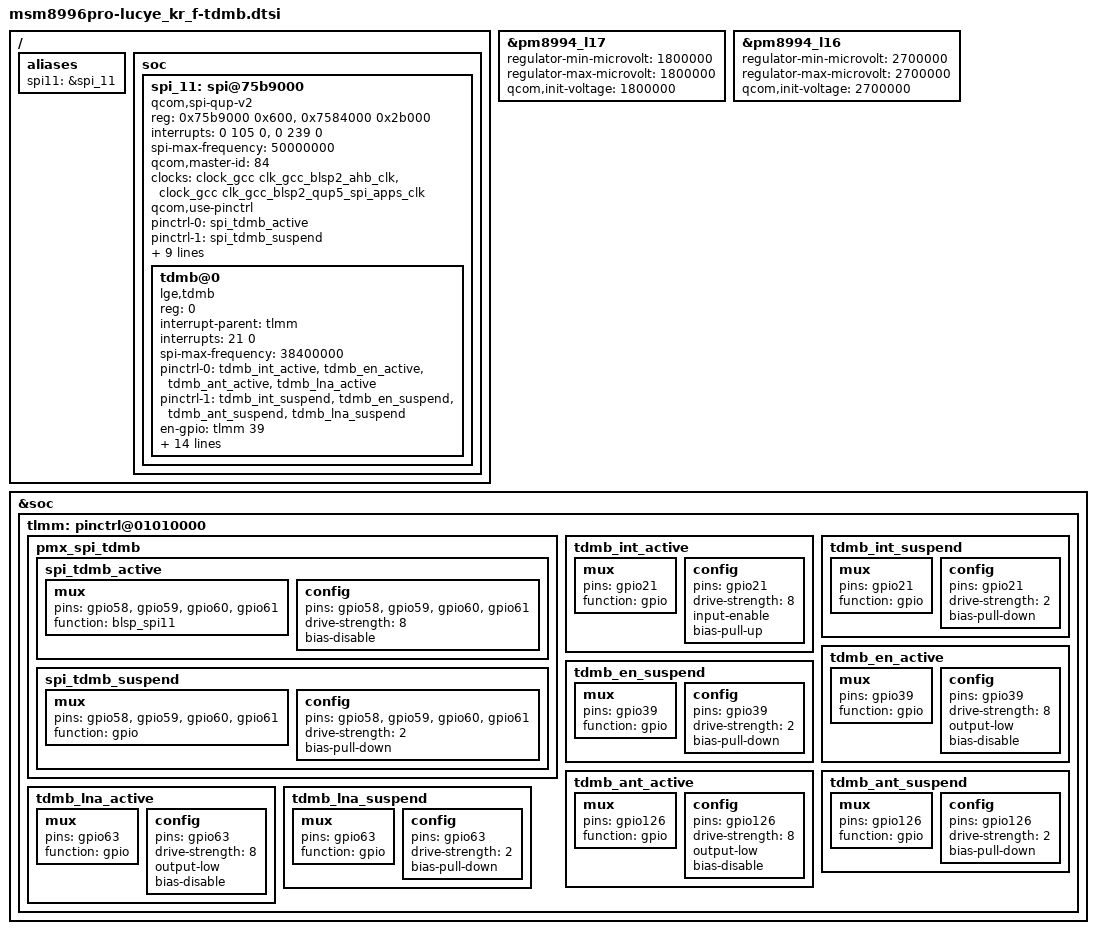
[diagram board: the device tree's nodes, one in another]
/* Copyright (c) 2014, The Linux Foundation. All rights reserved.
 *
 * This program is free software; you can redistribute it and/or modify
 * it under the terms of the GNU General Public License version 2 and
 * only version 2 as published by the Free Software Foundation.
 *
 * This program is distributed in the hope that it will be useful,
 * but WITHOUT ANY WARRANTY; without even the implied warranty of
 * MERCHANTABILITY or FITNESS FOR A PARTICULAR PURPOSE.  See the
 * GNU General Public License for more details.
 */

&pm8994_l17 {
	regulator-min-microvolt = <1800000>;
	regulator-max-microvolt = <1800000>;
	qcom,init-voltage = <1800000>;
	status = "ok";
};

&pm8994_l16 {
	regulator-min-microvolt = <2700000>;
	regulator-max-microvolt = <2700000>;
	qcom,init-voltage = <2700000>;
	status = "ok";
};

/ {
	aliases {
		spi11 = &spi_11;
	};

	soc {
		spi_11: spi@75b9000{	// [Modified] QUP_BASE address for BLSP# QUP# (ref. AP datasheet, This model use BLSP-2 QUP4)
			status = "ok";
			compatible = "qcom,spi-qup-v2"; // [Fixed] Should be "qcom,spi-qup-v2".

			// [Fixed] Address, size for slave chips.
			#address-cells = <1>;
			#size-cells = <0>;

			/* [Fixed] Resister region names referenced in reg.
				"spi_physical"     : Physical address of controller register blocks.
				when use BAM mode, add "spi_bam_physical"
				"spi_bam_physical" : Physical address of BAM controller.
				Keep the same names. */
			reg-names = "spi_physical", "spi_bam_physical";

			/* [Modified] Modify the reg field as below to add BLSP BAM base address (ref. AP datasheet)
				First Row is BLSP_QUP base address, size,
				Second Row is BAM address, size. */
			reg = <0x75b9000 0x600>, <0x7584000 0x2b000>;

			/* [Fixed] Interrupt resource names referenced in interrupts.
				"spi_irq"     : QUP-core interrupt
				when use BAM mode, add "spi_bam_irq"
				"spi_bam_irq" : BAM interrupt
				Keep the same names. */
			interrupt-names = "spi_irq", "spi_bam_irq";

			/* [Modified] Replace the interrupt filed. (ref. AP datasheet)
				First Field  : SPI interrupt, keep 0
				Second Field : Interrupt #
				Third Field  : Trigger type, keep 0
				First Row is BLSP_QUP base, Second Row is BAM. */
			interrupts = <0 105 0>, <0 239 0>;

			// [Fixed] Specifies maximum SPI clock frequency of AP(50 MHz). (ref. QCT SPI datasheet)
			spi-max-frequency = <50000000>;

			// [Modified] BLSP bus master ID. (ref. AP datasheet)
			qcom,master-id = <84>;

			// [Fixed] Set up the clocks, Keep the same names.
			clock-names = "iface_clk", "core_clk";
			/* [Modified]
				Add node to BLSP# AHB clock,
				Add node to QUP Core clock (BLSP# QUP#)
				Note : In clock QUP Core is label #1 to X. So QUP0 would be label as QUP1. */
			clocks = <&clock_gcc clk_gcc_blsp2_ahb_clk>, <&clock_gcc clk_gcc_blsp2_qup5_spi_apps_clk>;

			// [Fixed] When use pinctrl, enable.
			qcom,use-pinctrl;
			// [Fixed] Must contain "spi_default" and "spi_sleep" if pinctrl is to be used. Keep the same names.
			pinctrl-names = "spi_default","spi_sleep";
			/* [Fixed] List of phandles, each pointing at a pin configuration node within a pin controller.
				The list of names to assign states, List entry 0 defines the name for integer state ID 0... */
			pinctrl-0 = <&spi_tdmb_active>;
			pinctrl-1 = <&spi_tdmb_suspend>;

			/* [Modified] Set SPI GPIO (mosi, miso, cs, clk)
				tlmm is the parent, second # is gpio #, third flag keep it 0. */
			qcom,gpio-mosi = <&tlmm 58 0x00>;
			qcom,gpio-miso = <&tlmm 59 0x00>;
			qcom,gpio-cs0 = <&tlmm 60 0x00>;
			qcom,gpio-clk = <&tlmm 61 0x00>;

			// [Fixed] QUP uses infinite-mode. set zero
			qcom,infinite-mode = <0>;
			// [Fixed] When use BAM mode, enable.
			qcom,use-bam;
			// [Fixed] Version register exists.
			qcom,ver-reg-exists;
			// [Modified] Add consumer and producer pipes (ref. AP datasheet)
			qcom,bam-consumer-pipe-index = <20>; // Consumer pipe from AP BLSP SPI pipe assignment
			qcom,bam-producer-pipe-index = <21>; // Producer pipe from AP BLSP SPI pipe assignment
		};
	};
};

&spi_11 {
        tdmb@0 {
            compatible = "lge,tdmb"; // [Fixed] Should be "lge,tdmb".
	    reg = <0>;

            /* [Fixed] parents's node name ("tlmm" on sm8996) */
            interrupt-parent = <&tlmm>;

            /* [Modified] Set DMB_INT GPIO, first # is gpio #, second flag keep it 0. */
            interrupts = <21 0>;

            /* [Fixed] Specifies maximum SPI clock frequency of DMB chipset(38.4 MHz). (ref. FC8080 datasheet) */
            spi-max-frequency = <38400000>;

            /* [Fixed] The list of names to assign states, List entry 0,1,2... define the name for integer state ID 0,1,2...
                        - tdmb_pin_active : set to pinctrl-0 list (set to active)
                        - tdmb_pin_sleep : set to pinctrl-1 list (set to sleep) 	*/
            pinctrl-names = "tdmb_pin_active", "tdmb_pin_sleep";

            /* [Modified] The pin cofig lists can be for control pin.
                            - pinctrl-0 : active state
                            - pinctrl-1 : active sleep(suspend)
                          The pin config lists shall be defined in the "(model)-pinctrl.dtsi" file
                          The control pins lists are interrupt(tdmb_int), enable(tdmb_en),
                          FM/DMB antenna swtiching(tdmb_ant), LNA gain control & enable(tdmb_lna), LDO enable(tdmb_lna_en)
                          Additional items may vary depending on model schematic. */
            pinctrl-0 = <&tdmb_int_active>, <&tdmb_en_active>, <&tdmb_ant_active>, <&tdmb_lna_active>;
            pinctrl-1 = <&tdmb_int_suspend>, <&tdmb_en_suspend>, <&tdmb_ant_suspend>, <&tdmb_lna_suspend>;

            /* [Modified] first is parents's node, second # is gpio #, third flag keep it 0. */
            en-gpio = <&tlmm 39 0>;
            lna-gc-gpio = <&tlmm 63 0>;
            //lna-en-gpio = <&tlmm 164 0>;
            //ldo-en-gpio = <&tlmm 11 0>;

            /* [Modified] when use DMB_EN & LDO_EN same gpio, change below property to 1 */
            dmb-en-lna-en-same-gpio = <0>;


            /* [ANT Switch Information]
             *  1) FM/DMB Switch                               : Control
             *  2) TDMB ANT connected to port1 (High) and FM_ANT connected to port2 (Low), so active mode is high
             */

            /* [Modified] when use ant switching, change use-ant-sw to 1, and set ant active mode (high(1) or low(0)), ant-gpio.
               ant-sw-apio should be dmb_ant's Gpio number */
            use-ant-sw = <1>;
            ant-sw-gpio = <&tlmm 126 0>;
            ant-sw-active-value = <0>;

            /* [CLK Information] */
            /* [Modified] when use pmic clk buffer, change use-xtal to 0 and set xtal-freq(DMB Chipset Core clk), interface-freq(SPI interface clk) inter value in kHz. */
            use-xtal = <0>;
            xtal-freq = <19200>;
            interface-freq = <19200>;

            /* [Modified] when using clock buffer, you should check which clock buffer used for dmb device */
            clock-names = "tdmb_xo";
            clocks = <&clock_gcc clk_bb_clk2>;

            /* [Power Supply Description Information]
             *  1) ANT-SW LDO   (pm8150_l16)                 : V2.7, Not always power, power on/off control need
             *  2) DMB LDO      (pm8150_l12)                    : V1.8, always power, power on/off control not need
             *  3) LNA LDO      (pm8150_s4)                     : V1.8, always power, power on/off control not need
             */

            /* [Modified] When use ldo for RFSW, change ctrl-ant-sw-ldo to 1, and ant-sw-supply set the appropriate chipset & power function such as <&pm8953_l10>
               If no use case, change ctrl-ant-sw-ldo to 0, and ant-sw-supply set such as <&chipset#_l??>*/
            ctrl-ant-sw-ldo = <0>;
            //ant-sw-ldo-supply = <&chipset#_l??>;

            /* [Modified] when use ldo for LDO_IN, change ctrl-dmb-ldo to 1, and dmb-ldo-supply set the appropriate chipset & power function such as <&pm8953_l10>
              If no use case, change ctrl-dmb-ldo to 0, and dmb-ldo-supply set such as <&chipset#_l??>*/
            ctrl-dmb-ldo = <1>;
            dmb-ldo-supply = <&pm8994_l17>;

            /* [Modified] when use ldo for LNA(U1800), change ctrl-lna-ldo to 1, and lna-ldo-supply set the appropriate chipset & power function such as <&pm8953_l10>
               If no use case, change ctrl-lna-ldo to 0, and lna-ldo-supply set such as <&chipset#_l??>*/
            ctrl-lna-ldo = <1>;
            lna_ldo-supply = <&pm8994_l16>;
        };
};

&soc {
    tlmm: pinctrl@01010000 {
        pmx_spi_tdmb {
            spi_tdmb_active: spi_tdmb_active {
                mux {
                    pins =  "gpio58", "gpio59", "gpio60", "gpio61";
                    function = "blsp_spi11";
                };

                config {
                    pins =  "gpio58", "gpio59", "gpio60", "gpio61";
                    drive-strength = <8>; /* 8mA */
                    bias-disable;
                };
            };

            spi_tdmb_suspend: spi_tdmb_suspend {
                mux {
                    pins =  "gpio58", "gpio59", "gpio60", "gpio61";
                    function = "gpio";
                };

                config {
                    pins =  "gpio58", "gpio59", "gpio60", "gpio61";
                    drive-strength = <2>; /* 2mA */
                    bias-pull-down;
                };
            };
        };

        tdmb_int_active: tdmb_int_active {
            mux {
                pins = "gpio21";
                function = "gpio";
            };

            config {
                pins = "gpio21";
                drive-strength = <8>; /* 8mA */
                input-enable;
                bias-pull-up;
            };
        };

        tdmb_int_suspend: tdmb_int_suspend {
            mux {
                pins = "gpio21";
                function = "gpio";
            };

            config {
                pins = "gpio21";
                drive-strength = <2>;
                bias-pull-down;
            };
        };

        tdmb_en_active: tdmb_en_active {
            mux {
                pins = "gpio39";
                function = "gpio";
            };

            config {
                pins = "gpio39";
                drive-strength = <8>; /* 8mA */
                output-low;
                bias-disable;
            };
        };

        tdmb_en_suspend: tdmb_en_suspend {
            mux {
                pins = "gpio39";
                function = "gpio";
            };

            config {
                pins = "gpio39";
                drive-strength = <2>;
                bias-pull-down;
            };
        };


        tdmb_ant_active: tdmb_ant_active {
            mux {
                pins = "gpio126";
                function = "gpio";
            };

            config {
                pins = "gpio126";
                drive-strength = <8>;
                output-low;
                bias-disable;
            };
        };

        tdmb_ant_suspend: tdmb_ant_suspend {
            mux {
                pins = "gpio126";
                function = "gpio";
            };

            config {
                pins = "gpio126";
                drive-strength = <2>;
                bias-pull-down;
            };
        };

        tdmb_lna_active: tdmb_lna_active {
            mux {
                pins = "gpio63";
                function = "gpio";
            };

            config {
                pins = "gpio63";
                drive-strength = <8>; /* 8mA */
                output-low;
                bias-disable;
            };
        };

        tdmb_lna_suspend: tdmb_lna_suspend {
            mux {
                pins = "gpio63";
                function = "gpio";
            };

            config {
                pins = "gpio63";
                drive-strength = <2>;
                bias-pull-down;
            };
        };
    };
};
